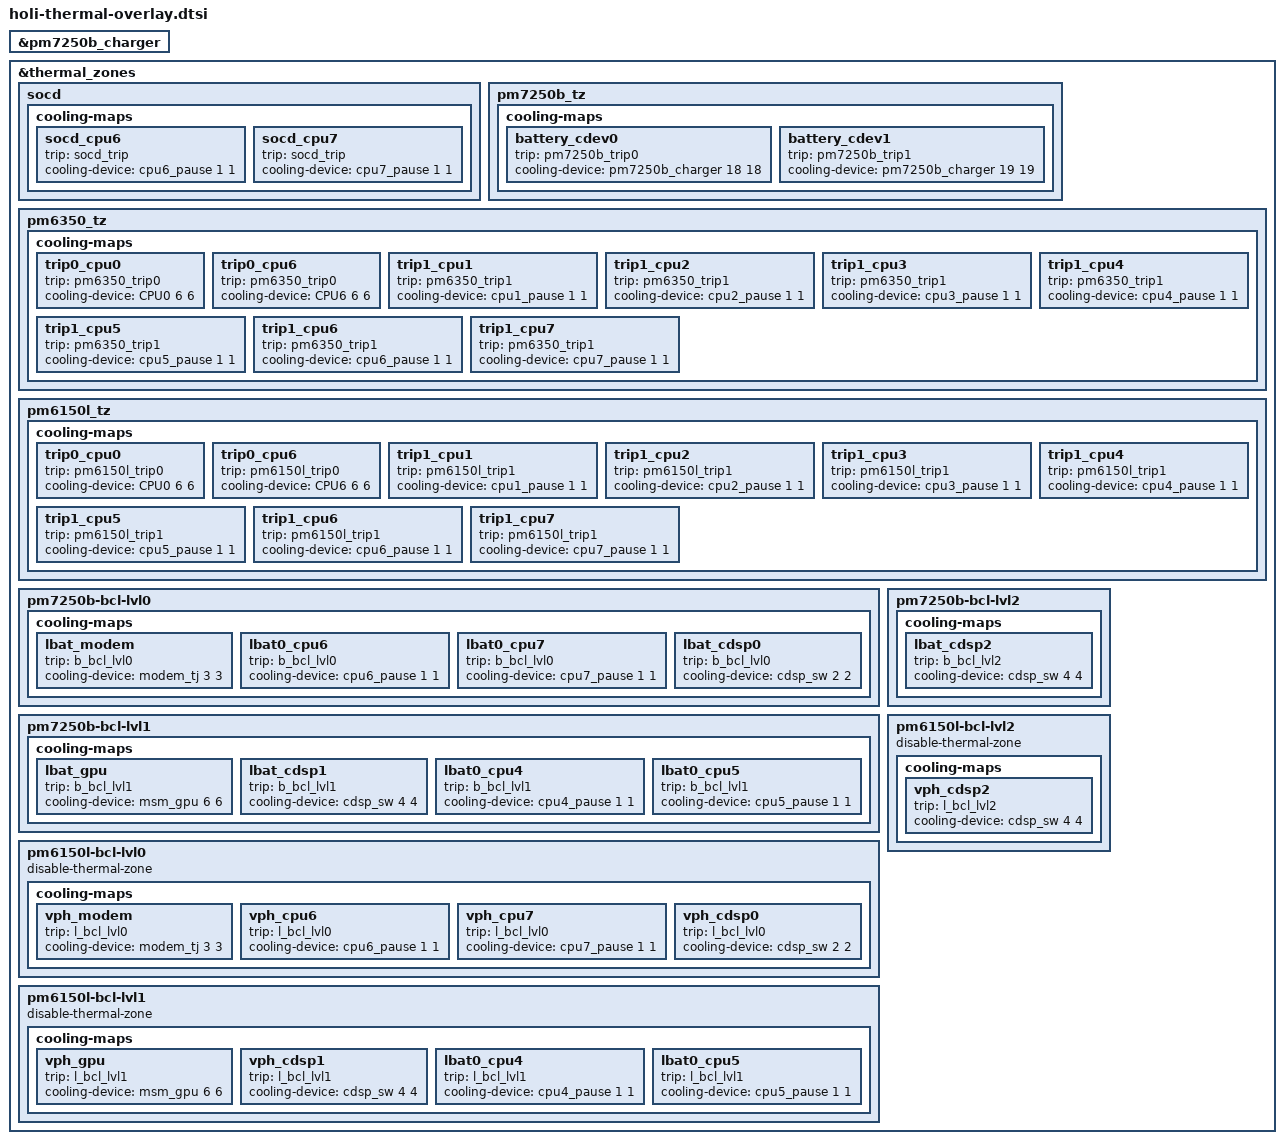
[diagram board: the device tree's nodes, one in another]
#include <dt-bindings/thermal/thermal.h>

&pm7250b_charger {
	#cooling-cells = <2>;
};

&thermal_zones {
	socd {
		cooling-maps {
			socd_cpu6 {
				trip = <&socd_trip>;
				cooling-device = <&cpu6_pause 1 1>;
			};

			socd_cpu7 {
				trip = <&socd_trip>;
				cooling-device = <&cpu7_pause 1 1>;
			};
		};
	};

	pm7250b_tz {
		cooling-maps {
			battery_cdev0 {
				trip = <&pm7250b_trip0>;
				cooling-device = <&pm7250b_charger 18 18>;
			};

			battery_cdev1 {
				trip = <&pm7250b_trip1>;
				cooling-device = <&pm7250b_charger 19 19>;
			};
		};
	};

	pm6350_tz {
		cooling-maps {
			trip0_cpu0 {
				trip = <&pm6350_trip0>;
				cooling-device = <&CPU0 6 6>;
			};

			trip0_cpu6 {
				trip = <&pm6350_trip0>;
				cooling-device = <&CPU6 6 6>;
			};

			trip1_cpu1 {
				trip = <&pm6350_trip1>;
				cooling-device = <&cpu1_pause 1 1>;
			};

			trip1_cpu2 {
				trip = <&pm6350_trip1>;
				cooling-device = <&cpu2_pause 1 1>;
			};

			trip1_cpu3 {
				trip = <&pm6350_trip1>;
				cooling-device = <&cpu3_pause 1 1>;
			};

			trip1_cpu4 {
				trip = <&pm6350_trip1>;
				cooling-device = <&cpu4_pause 1 1>;
			};

			trip1_cpu5 {
				trip = <&pm6350_trip1>;
				cooling-device = <&cpu5_pause 1 1>;
			};

			trip1_cpu6 {
				trip = <&pm6350_trip1>;
				cooling-device = <&cpu6_pause 1 1>;
			};

			trip1_cpu7 {
				trip = <&pm6350_trip1>;
				cooling-device = <&cpu7_pause 1 1>;
			};
		};
	};

	pm6150l_tz {
		cooling-maps {
			trip0_cpu0 {
				trip = <&pm6150l_trip0>;
				cooling-device = <&CPU0 6 6>;
			};

			trip0_cpu6 {
				trip = <&pm6150l_trip0>;
				cooling-device = <&CPU6 6 6>;
			};

			trip1_cpu1 {
				trip = <&pm6150l_trip1>;
				cooling-device = <&cpu1_pause 1 1>;
			};

			trip1_cpu2 {
				trip = <&pm6150l_trip1>;
				cooling-device = <&cpu2_pause 1 1>;
			};

			trip1_cpu3 {
				trip = <&pm6150l_trip1>;
				cooling-device = <&cpu3_pause 1 1>;
			};

			trip1_cpu4 {
				trip = <&pm6150l_trip1>;
				cooling-device = <&cpu4_pause 1 1>;
			};

			trip1_cpu5 {
				trip = <&pm6150l_trip1>;
				cooling-device = <&cpu5_pause 1 1>;
			};

			trip1_cpu6 {
				trip = <&pm6150l_trip1>;
				cooling-device = <&cpu6_pause 1 1>;
			};

			trip1_cpu7 {
				trip = <&pm6150l_trip1>;
				cooling-device = <&cpu7_pause 1 1>;
			};
		};
	};

	pm7250b-bcl-lvl0 {
		cooling-maps {
			lbat_modem {
				trip = <&b_bcl_lvl0>;
				cooling-device = <&modem_tj 3 3>;
			};

			lbat0_cpu6 {
				trip = <&b_bcl_lvl0>;
				cooling-device = <&cpu6_pause 1 1>;
			};

			lbat0_cpu7 {
				trip = <&b_bcl_lvl0>;
				cooling-device = <&cpu7_pause 1 1>;
			};

			lbat_cdsp0 {
				trip = <&b_bcl_lvl0>;
				cooling-device = <&cdsp_sw 2 2>;
			};
		};
	};

	pm7250b-bcl-lvl1 {
		cooling-maps {
			lbat_gpu {
				trip = <&b_bcl_lvl1>;
				cooling-device = <&msm_gpu 6 6>;
			};

			lbat_cdsp1 {
				trip = <&b_bcl_lvl1>;
				cooling-device = <&cdsp_sw 4 4>;
			};

			lbat0_cpu4 {
				trip = <&b_bcl_lvl1>;
				cooling-device = <&cpu4_pause 1 1>;
			};

			lbat0_cpu5 {
				trip = <&b_bcl_lvl1>;
				cooling-device = <&cpu5_pause 1 1>;
			};
		};
	};

	pm7250b-bcl-lvl2 {
		cooling-maps {
			lbat_cdsp2 {
				trip = <&b_bcl_lvl2>;
				cooling-device = <&cdsp_sw 4 4>;
			};
		};
	};

	pm6150l-bcl-lvl0 {
		disable-thermal-zone;
		cooling-maps {
			vph_modem {
				trip = <&l_bcl_lvl0>;
				cooling-device = <&modem_tj 3 3>;
			};

			vph_cpu6 {
				trip = <&l_bcl_lvl0>;
				cooling-device = <&cpu6_pause 1 1>;
			};

			vph_cpu7 {
				trip = <&l_bcl_lvl0>;
				cooling-device = <&cpu7_pause 1 1>;
			};

			vph_cdsp0 {
				trip = <&l_bcl_lvl0>;
				cooling-device = <&cdsp_sw 2 2>;
			};
		};
	};

	pm6150l-bcl-lvl1 {
		disable-thermal-zone;
		cooling-maps {
			vph_gpu {
				trip = <&l_bcl_lvl1>;
				cooling-device = <&msm_gpu 6 6>;
			};

			vph_cdsp1 {
				trip = <&l_bcl_lvl1>;
				cooling-device = <&cdsp_sw 4 4>;
			};

			lbat0_cpu4 {
				trip = <&l_bcl_lvl1>;
				cooling-device = <&cpu4_pause 1 1>;
			};

			lbat0_cpu5 {
				trip = <&l_bcl_lvl1>;
				cooling-device = <&cpu5_pause 1 1>;
			};
		};
	};

	pm6150l-bcl-lvl2 {
		disable-thermal-zone;
		cooling-maps {
			vph_cdsp2 {
				trip = <&l_bcl_lvl2>;
				cooling-device = <&cdsp_sw 4 4>;
			};
		};
	};
};
